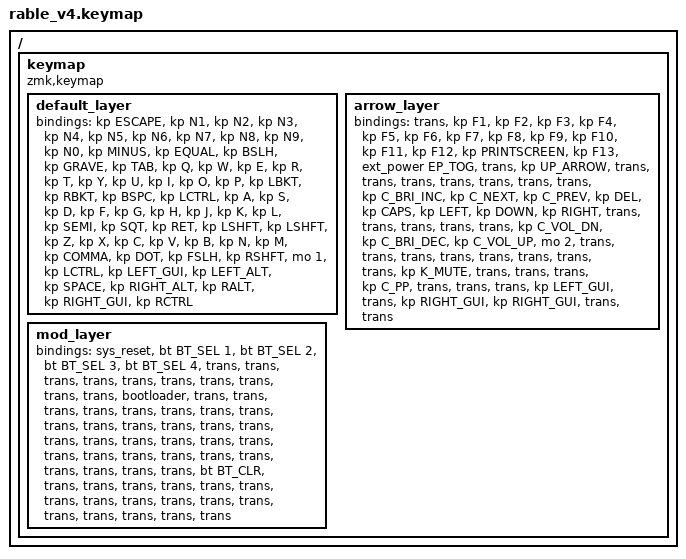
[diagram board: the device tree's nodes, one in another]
/*
 * Copyright (c) 2021 Nick Winans
 *
 * SPDX-License-Identifier: MIT
 */

#include <behaviors.dtsi>
#include <dt-bindings/zmk/bt.h>
#include <dt-bindings/zmk/ext_power.h>
#include <dt-bindings/zmk/keys.h>

/ {
    keymap {
        compatible = "zmk,keymap";

        default_layer {
            bindings = <
&kp ESCAPE  &kp N1  &kp N2  &kp N3  &kp N4  &kp N5  &kp N6  &kp N7  &kp N8  &kp N9  &kp N0  &kp MINUS  &kp EQUAL  &kp BSLH  &kp GRAVE  &kp TAB  &kp Q  &kp W  &kp E  &kp R  &kp T  &kp Y  &kp U  &kp I  &kp O  &kp P  &kp LBKT  &kp RBKT  &kp BSPC  &kp LCTRL  &kp A  &kp S  &kp D  &kp F  &kp G  &kp H  &kp J  &kp K  &kp L  &kp SEMI  &kp SQT  &kp RET  &kp LSHFT  &kp LSHFT  &kp Z  &kp X  &kp C  &kp V  &kp B  &kp N  &kp M  &kp COMMA  &kp DOT  &kp FSLH  &kp RSHFT  &mo 1  &kp LCTRL  &kp LEFT_GUI  &kp LEFT_ALT  &kp SPACE  &kp RIGHT_ALT  &kp RALT  &kp RIGHT_GUI  &kp RCTRL
            >;
        };

        arrow_layer {
            // ----------------------------------------------------------------------------------------------------------------
            // |        |    |     |     |     |     |     |     |     |     |     |     |     |     |     |   `~    |
            // |        |    |     |     |     |     |     |     |     |     |     |     |     |     |     |         |
            // |        |    |     |     |     |     |     |LEFT |DOWN |  UP |RIGHT|     |     |     |     |         |
            // |        |    |     |     |     |     |     |     |     |     |     |     |     |     |     |         |
            // |        |    |     |     |                                               |     |     |     |         |
            // ----------------------------------------------------------------------------------------------------------------

            bindings = <
&trans  &kp F1  &kp F2  &kp F3  &kp F4  &kp F5  &kp F6  &kp F7  &kp F8  &kp F9  &kp F10  &kp F11  &kp F12  &kp PRINTSCREEN  &kp F13  &ext_power EP_TOG  &trans  &kp UP_ARROW  &trans  &trans  &trans  &trans  &trans  &trans  &trans  &kp C_BRI_INC  &kp C_NEXT  &kp C_PREV  &kp DEL  &kp CAPS  &kp LEFT  &kp DOWN  &kp RIGHT  &trans  &trans  &trans  &trans  &trans  &kp C_VOL_DN  &kp C_BRI_DEC  &kp C_VOL_UP  &mo 2  &trans  &trans  &trans  &trans  &trans  &trans  &trans  &trans  &kp K_MUTE  &trans  &trans  &trans  &kp C_PP  &trans  &trans  &trans  &kp LEFT_GUI  &trans  &kp RIGHT_GUI  &kp RIGHT_GUI  &trans  &trans
            >;
        };

        mod_layer {
            // ----------------------------------------------------------------------------------------------------------------
            // |        |    | BT 1|BT 2 |BT 3 |BT 4 |     |     |     |     |     |     |     |     |BT CLR |         |
            // |        |    | RST | BOOT|     |     |     |     |     |     |     |     |     |     |       |         |
            // |        |    | USB | BLE |     |     |     |     |     |     |     |     |     |     |RGB TOG|         |
            // |        |    |EP_ON|EP_OFF|EP_TOG|     |     |     |     |     |     |     |     |     |       |         |
            // |        |    |     |     |                                               |     |     |       |         |
            // ----------------------------------------------------------------------------------------------------------------

            bindings = <
&sys_reset  &bt BT_SEL 1  &bt BT_SEL 2  &bt BT_SEL 3  &bt BT_SEL 4  &trans  &trans  &trans  &trans  &trans  &trans  &trans  &trans  &trans  &trans  &bootloader  &trans  &trans  &trans  &trans  &trans  &trans  &trans  &trans  &trans  &trans  &trans  &trans  &trans  &trans  &trans  &trans  &trans  &trans  &trans  &trans  &trans  &trans  &trans  &trans  &trans  &trans  &trans  &trans  &trans  &trans  &bt BT_CLR  &trans  &trans  &trans  &trans  &trans  &trans  &trans  &trans  &trans  &trans  &trans  &trans  &trans  &trans  &trans  &trans  &trans
            >;
        };
    };
};
